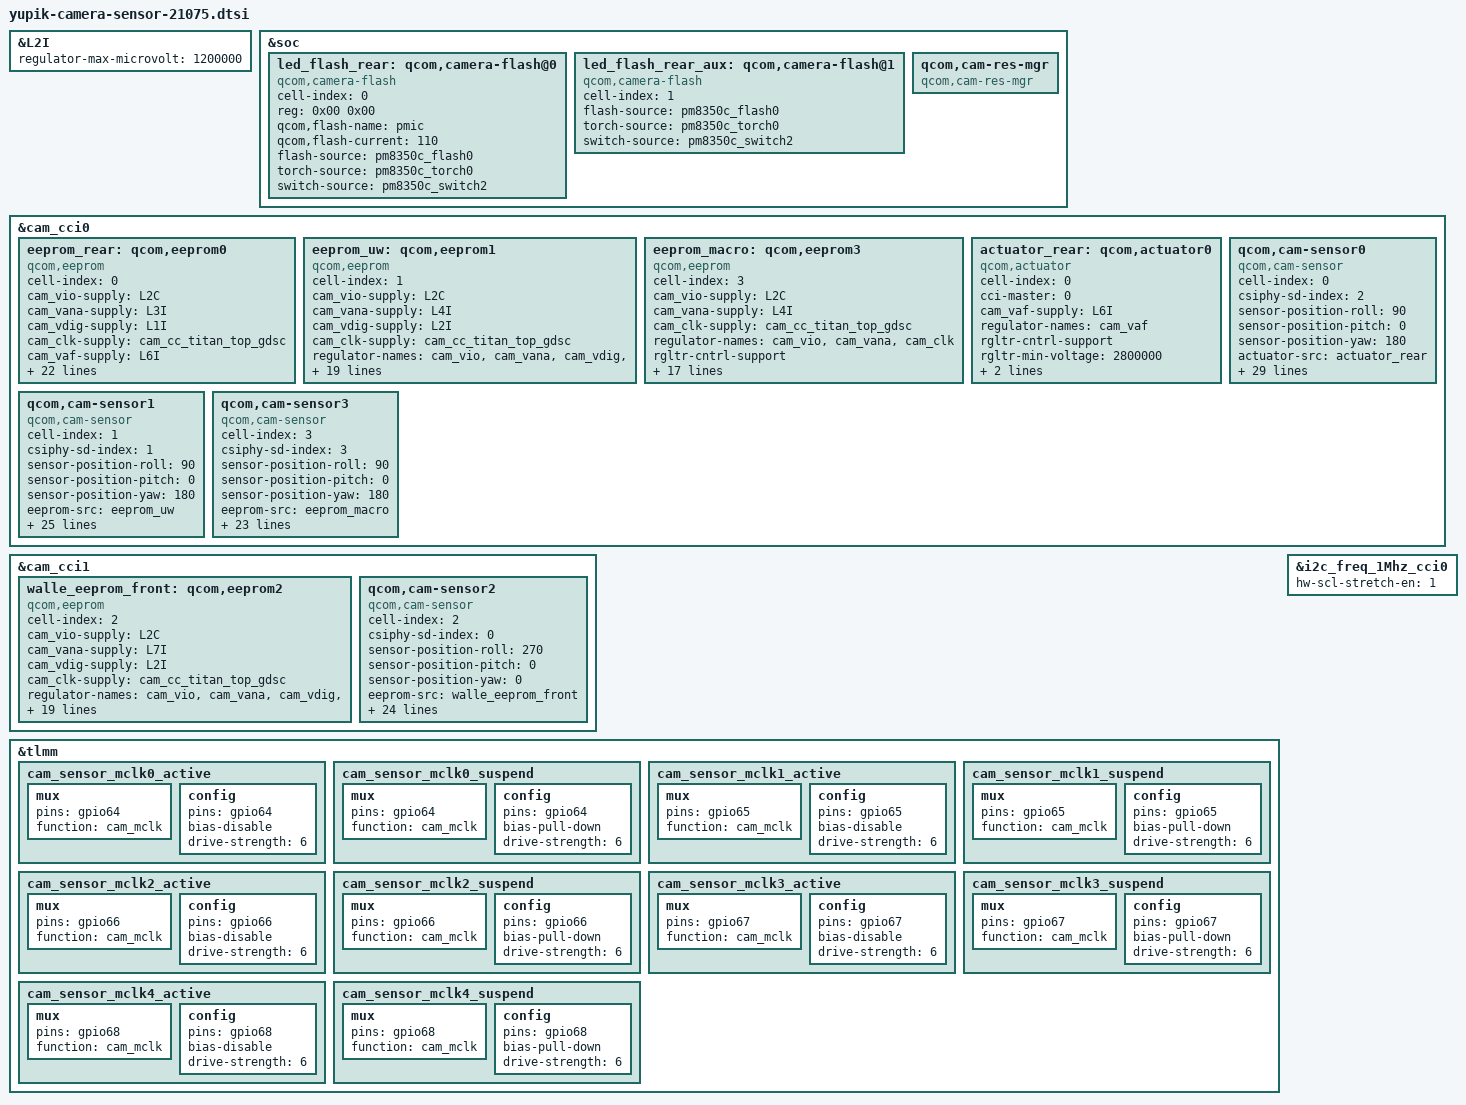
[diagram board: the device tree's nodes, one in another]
#include <dt-bindings/clock/qcom,camcc-yupik.h>

&L2I {
    regulator-max-microvolt = <1200000>;
};

&soc {
	led_flash_rear: qcom,camera-flash@0 {
		cell-index = <0>;
		reg = <0x00 0x00>;
	        compatible = "qcom,camera-flash";
		qcom,flash-name = "pmic";
		qcom,flash-current = <110>;
		flash-source = <&pm8350c_flash0>;
		torch-source = <&pm8350c_torch0>;
		switch-source = <&pm8350c_switch2>;
		status = "ok";
	};
	led_flash_rear_aux: qcom,camera-flash@1 {
		cell-index = <1>;
		compatible = "qcom,camera-flash";
		flash-source = <&pm8350c_flash0>;
		torch-source = <&pm8350c_torch0>;
		switch-source = <&pm8350c_switch2>;
		status = "ok";
	};
	qcom,cam-res-mgr {
		compatible = "qcom,cam-res-mgr";
		status = "ok";
	};
};

&cam_cci0 {
	eeprom_rear: qcom,eeprom0 {
		cell-index = <0>;
		compatible = "qcom,eeprom";
		cam_vio-supply = <&L2C>;
		cam_vana-supply = <&L3I>;
		cam_vdig-supply = <&L1I>;
		cam_clk-supply = <&cam_cc_titan_top_gdsc>;
		cam_vaf-supply = <&L6I>;
		regulator-names = "cam_vio", "cam_vana",
                           "cam_vdig","cam_clk","cam_vaf";
		rgltr-cntrl-support;
		rgltr-min-voltage = <1800000 2800000 1120000 0 2800000>;
		rgltr-max-voltage = <1800000 2800000 1120000 0 2800000>;
		rgltr-load-current = <0 60000 105000 0 103000>;
		gpio-no-mux = <0>;
		pinctrl-names = "cam_default", "cam_suspend";
		pinctrl-0 = <&cam_sensor_mclk0_active
                    &cam_sensor_active_rst0>;
		pinctrl-1 = <&cam_sensor_mclk0_suspend
                    &cam_sensor_suspend_rst0>;
		gpios = <&tlmm 64 0>,
                <&tlmm 20 0>;
		gpio-reset = <1>;
		gpio-req-tbl-num = <0 1>;
		gpio-req-tbl-flags = <1 0>;
		gpio-req-tbl-label = "CAMIF_MCLK0", "CAM_RESET0";
		cci-master = <0>;
		status = "ok";
		clocks = <&camcc CAM_CC_MCLK0_CLK>;
		clock-names = "cam_clk";
		clock-cntl-level = "nominal";
		clock-rates = <24000000>;
	};

    eeprom_uw: qcom,eeprom1 {
		cell-index = <1>;
		compatible = "qcom,eeprom";
		cam_vio-supply = <&L2C>;
		cam_vana-supply = <&L4I>;
		cam_vdig-supply = <&L2I>;
		cam_clk-supply = <&cam_cc_titan_top_gdsc>;
		regulator-names = "cam_vio", "cam_vana", "cam_vdig", "cam_clk";
		rgltr-cntrl-support;
		rgltr-min-voltage = <1800000 2800000 1200000 0>;
		rgltr-max-voltage = <1800000 2800000 1200000 0>;
		rgltr-load-current = <0 50000 250000 0>;
		gpio-no-mux = <0>;
		pinctrl-names = "cam_default", "cam_suspend";
		pinctrl-0 = <&cam_sensor_mclk1_active
                    &cam_sensor_active_rst1>;
		pinctrl-1 = <&cam_sensor_mclk1_suspend
                    &cam_sensor_suspend_rst1>;
		gpios = <&tlmm 65 0>,
                <&tlmm 21 0>;
		gpio-reset = <1>;
		gpio-req-tbl-num = <0 1>;
		gpio-req-tbl-flags = <1 0>;
		gpio-req-tbl-label = "CAMIF_MCLK1",
		                     "CAM_RESET1";
		cci-master = <1>;
		status = "ok";
		clocks = <&camcc CAM_CC_MCLK1_CLK>;
		clock-names = "cam_clk";
		clock-cntl-level = "nominal";
		clock-rates = <24000000>;
	};

    eeprom_macro: qcom,eeprom3 {
		cell-index = <3>;
		compatible = "qcom,eeprom";
		cam_vio-supply = <&L2C>;
		cam_vana-supply = <&L4I>;
		cam_clk-supply = <&cam_cc_titan_top_gdsc>;
		regulator-names = "cam_vio", "cam_vana", "cam_clk";
		rgltr-cntrl-support;
		rgltr-min-voltage = <1800000 2800000 0>;
		rgltr-max-voltage = <1800000 2800000 0>;
		rgltr-load-current = <0 80000 0>;
		gpio-no-mux = <0>;
		pinctrl-names = "cam_default", "cam_suspend";
		pinctrl-0 = <&cam_sensor_mclk3_active
				 &cam_sensor_active_rst3>;
		pinctrl-1 = <&cam_sensor_mclk3_suspend
				 &cam_sensor_suspend_rst3>;
		gpios = <&tlmm 67 0>,
		        <&tlmm 78 0>;
		gpio-reset = <1>;
		gpio-req-tbl-num = <0 1>;
		gpio-req-tbl-flags = <1 0>;
		gpio-req-tbl-label = "CAMIF_MCLK3",
		                     "CAM_RESET3";
		cci-master = <1>;
		status = "ok";
		clocks = <&camcc CAM_CC_MCLK3_CLK>;
		clock-names = "cam_clk";
		clock-cntl-level = "turbo";
		clock-rates = <24000000>;
	};

	actuator_rear: qcom,actuator0 {
		cell-index = <0>;
		compatible = "qcom,actuator";
		cci-master = <0>;
		cam_vaf-supply = <&L6I>;
		regulator-names = "cam_vaf";
		rgltr-cntrl-support;
		rgltr-min-voltage = <2800000>;
		rgltr-max-voltage = <2800000>;
		rgltr-load-current = <103000>;
	};

	/* Wide */
	qcom,cam-sensor0 {
		cell-index = <0>;
		compatible = "qcom,cam-sensor";
		csiphy-sd-index = <2>;
		sensor-position-roll = <90>;
		sensor-position-pitch = <0>;
		sensor-position-yaw = <180>;
		actuator-src = <&actuator_rear>;
		eeprom-src = <&eeprom_rear>;
		led-flash-src = <&led_flash_rear>;
		cam_vio-supply = <&L2C>;
		cam_vana-supply = <&L3I>;
		cam_vdig-supply = <&L1I>;
		cam_clk-supply = <&cam_cc_titan_top_gdsc>;
		cam_vaf-supply = <&L6I>;
		regulator-names = "cam_vio", "cam_vana",
                           "cam_vdig","cam_clk","cam_vaf";
		rgltr-cntrl-support;
		rgltr-min-voltage = <1800000 2800000 1120000 0 2800000>;
		rgltr-max-voltage = <1800000 2800000 1120000 0 2800000>;
		rgltr-load-current = <0 60000 105000 0 103000>;
		gpio-no-mux = <0>;
		pinctrl-names = "cam_default", "cam_suspend";
		pinctrl-0 = <&cam_sensor_mclk0_active
                    &cam_sensor_active_rst0>;
		pinctrl-1 = <&cam_sensor_mclk0_suspend
                    &cam_sensor_suspend_rst0>;
		gpios = <&tlmm 64 0>,
                <&tlmm 20 0>;
		gpio-reset = <1>;
		gpio-req-tbl-num = <0 1>;
		gpio-req-tbl-flags = <1 0>;
		gpio-req-tbl-label = "CAMIF_MCLK0", "CAM_RESET0";
		cci-master = <0>;
		status = "ok";
		clocks = <&camcc CAM_CC_MCLK0_CLK>;
		clock-names = "cam_clk";
		clock-cntl-level = "nominal";
		clock-rates = <24000000>;
	};

	/* UW */
	qcom,cam-sensor1 {
		cell-index = <1>;
		compatible = "qcom,cam-sensor";
		csiphy-sd-index = <1>;
		sensor-position-roll = <90>;
		sensor-position-pitch = <0>;
		sensor-position-yaw = <180>;
        eeprom-src = <&eeprom_uw>;
		led-flash-src = <&led_flash_rear_aux>;
		cam_vio-supply = <&L2C>;
		cam_vana-supply = <&L4I>;
		cam_vdig-supply = <&L2I>;
		cam_clk-supply = <&cam_cc_titan_top_gdsc>;
		regulator-names = "cam_vio", "cam_vana", "cam_vdig", "cam_clk";
		rgltr-cntrl-support;
		rgltr-min-voltage = <1800000 2800000 1200000 0>;
		rgltr-max-voltage = <1800000 2800000 1200000 0>;
		rgltr-load-current = <0 50000 250000 0>;
		gpio-no-mux = <0>;
		pinctrl-names = "cam_default", "cam_suspend";
		pinctrl-0 = <&cam_sensor_mclk1_active
                    &cam_sensor_active_rst1>;
		pinctrl-1 = <&cam_sensor_mclk1_suspend
                    &cam_sensor_suspend_rst1>;
		gpios = <&tlmm 65 0>,
                <&tlmm 21 0>;
		gpio-reset = <1>;
		gpio-req-tbl-num = <0 1>;
		gpio-req-tbl-flags = <1 0>;
		gpio-req-tbl-label = "CAMIF_MCLK1",
		                     "CAM_RESET1";
		cci-master = <1>;
		status = "ok";
		clocks = <&camcc CAM_CC_MCLK1_CLK>;
		clock-names = "cam_clk";
		clock-cntl-level = "nominal";
		clock-rates = <24000000>;
	};

	/* Macro */
	qcom,cam-sensor3 {
		cell-index = <3>;
		compatible = "qcom,cam-sensor";
		csiphy-sd-index = <3>;
		sensor-position-roll = <90>;
		sensor-position-pitch = <0>;
		sensor-position-yaw = <180>;
        eeprom-src = <&eeprom_macro>;
		led-flash-src = <&led_flash_rear>;
		cam_vio-supply = <&L2C>;
		cam_vana-supply = <&L4I>;
		cam_clk-supply = <&cam_cc_titan_top_gdsc>;
		regulator-names = "cam_vio", "cam_vana", "cam_clk";
		rgltr-cntrl-support;
		rgltr-min-voltage = <1800000 2800000 0>;
		rgltr-max-voltage = <1800000 2800000 0>;
		rgltr-load-current = <0 80000 0>;
		gpio-no-mux = <0>;
		pinctrl-names = "cam_default", "cam_suspend";
		pinctrl-0 = <&cam_sensor_mclk3_active
				 &cam_sensor_active_rst3>;
		pinctrl-1 = <&cam_sensor_mclk3_suspend
				 &cam_sensor_suspend_rst3>;
		gpios = <&tlmm 67 0>,
		        <&tlmm 78 0>;
		gpio-reset = <1>;
		gpio-req-tbl-num = <0 1>;
		gpio-req-tbl-flags = <1 0>;
		gpio-req-tbl-label = "CAMIF_MCLK3",
		                     "CAM_RESET3";
		cci-master = <1>;
		status = "ok";
		clocks = <&camcc CAM_CC_MCLK3_CLK>;
		clock-names = "cam_clk";
		clock-cntl-level = "turbo";
		clock-rates = <24000000>;
	};
};

&cam_cci1 {
	walle_eeprom_front: qcom,eeprom2 {
		cell-index = <2>;
		compatible = "qcom,eeprom";
        cam_vio-supply = <&L2C>;
        cam_vana-supply = <&L7I>;
        cam_vdig-supply = <&L2I>;
        cam_clk-supply = <&cam_cc_titan_top_gdsc>;
        regulator-names = "cam_vio", "cam_vana", "cam_vdig", "cam_clk";
        rgltr-cntrl-support;
        rgltr-min-voltage = <1800000 2800000 1056000 0>;
        rgltr-max-voltage = <1800000 2800000 1200000 0>;
        rgltr-load-current = <0 80000 105000 0>;
        gpio-no-mux = <0>;
        pinctrl-names = "cam_default", "cam_suspend";
        pinctrl-0 = <&cam_sensor_mclk2_active
                    &cam_sensor_active_rst2>;
        pinctrl-1 = <&cam_sensor_mclk2_suspend
                    &cam_sensor_suspend_rst2>;
        gpios = <&tlmm 66 0>,
                <&tlmm 77 0>;
        gpio-reset = <1>;
        gpio-req-tbl-num = <0 1>;
        gpio-req-tbl-flags = <1 0>;
        gpio-req-tbl-label = "CAMIF_MCLK2","CAM_RESET2";
        cci-master = <1>;
        status = "ok";
        clocks = <&camcc CAM_CC_MCLK2_CLK>;
        clock-names = "cam_clk";
        clock-cntl-level = "turbo";
        clock-rates = <24000000>;
	};

	/* Front */
	qcom,cam-sensor2 {
        cell-index = <2>;
        compatible = "qcom,cam-sensor";
        csiphy-sd-index = <0>;
        sensor-position-roll = <270>;
        sensor-position-pitch = <0>;
        sensor-position-yaw = <0>;
        eeprom-src = <&walle_eeprom_front>;
        cam_vio-supply = <&L2C>;
        cam_vana-supply = <&L7I>;
        cam_vdig-supply = <&L2I>;
        cam_clk-supply = <&cam_cc_titan_top_gdsc>;
        regulator-names = "cam_vio", "cam_vana", "cam_vdig", "cam_clk";
        rgltr-cntrl-support;
        rgltr-min-voltage = <1800000 2800000 1056000 0>;
        rgltr-max-voltage = <1800000 2800000 1200000 0>;
        rgltr-load-current = <0 80000 105000 0>;
        gpio-no-mux = <0>;
        pinctrl-names = "cam_default", "cam_suspend";
        pinctrl-0 = <&cam_sensor_mclk2_active
                    &cam_sensor_active_rst2>;
        pinctrl-1 = <&cam_sensor_mclk2_suspend
                    &cam_sensor_suspend_rst2>;
        gpios = <&tlmm 66 0>,
                <&tlmm 77 0>;
        gpio-reset = <1>;
        gpio-req-tbl-num = <0 1>;
        gpio-req-tbl-flags = <1 0>;
        gpio-req-tbl-label = "CAMIF_MCLK2","CAM_RESET2";
        cci-master = <1>;
        status = "ok";
        clocks = <&camcc CAM_CC_MCLK2_CLK>;
        clock-names = "cam_clk";
        clock-cntl-level = "turbo";
        clock-rates = <24000000>;
	};
};

&tlmm {

    cam_sensor_mclk0_active: cam_sensor_mclk0_active {
        /* MCLK0 */
        mux {
            pins = "gpio64";
            function = "cam_mclk";
        };

        config {
            pins = "gpio64";
            bias-disable; /* No PULL */
            drive-strength = <6>; /* 2 MA */
        };
    };

    cam_sensor_mclk0_suspend: cam_sensor_mclk0_suspend {
        /* MCLK0 */
        mux {
            pins = "gpio64";
            function = "cam_mclk";
        };

        config {
            pins = "gpio64";
            bias-pull-down; /* PULL DOWN */
            drive-strength = <6>; /* 2 MA */
        };
    };

    cam_sensor_mclk1_active: cam_sensor_mclk1_active {
        /* MCLK1 */
        mux {
            pins = "gpio65";
            function = "cam_mclk";
        };

        config {
            pins = "gpio65";
            bias-disable; /* No PULL */
            drive-strength = <6>; /* 2 MA */
        };
    };

    cam_sensor_mclk1_suspend: cam_sensor_mclk1_suspend {
        /* MCLK1 */
        mux {
            pins = "gpio65";
            function = "cam_mclk";
        };

        config {
            pins = "gpio65";
            bias-pull-down; /* PULL DOWN */
            drive-strength = <6>; /* 2 MA */
        };
    };

    cam_sensor_mclk2_active: cam_sensor_mclk2_active {
        /* MCLK2 */
        mux {
            pins = "gpio66";
            function = "cam_mclk";
        };

        config {
            pins = "gpio66";
            bias-disable; /* No PULL */
            drive-strength = <6>; /* 2 MA */
        };
    };

    cam_sensor_mclk2_suspend: cam_sensor_mclk2_suspend {
        /* MCLK2 */
        mux {
            pins = "gpio66";
            function = "cam_mclk";
        };

        config {
            pins = "gpio66";
            bias-pull-down; /* PULL DOWN */
            drive-strength = <6>; /* 2 MA */
        };
    };

    cam_sensor_mclk3_active: cam_sensor_mclk3_active {
        /* MCLK3 */
        mux {
            pins = "gpio67";
            function = "cam_mclk";
        };

        config {
            pins = "gpio67";
            bias-disable; /* No PULL */
            drive-strength = <6>; /* 2 MA */
        };
    };

    cam_sensor_mclk3_suspend: cam_sensor_mclk3_suspend {
        /* MCLK3 */
        mux {
            pins = "gpio67";
            function = "cam_mclk";
        };

        config {
            pins = "gpio67";
            bias-pull-down; /* PULL DOWN */
            drive-strength = <6>; /* 2 MA */
        };
    };

    cam_sensor_mclk4_active: cam_sensor_mclk4_active {
        /* MCLK4 */
        mux {
            pins = "gpio68";
            function = "cam_mclk";
        };

        config {
            pins = "gpio68";
            bias-disable; /* No PULL */
            drive-strength = <6>; /* 2 MA */
        };
    };

    cam_sensor_mclk4_suspend: cam_sensor_mclk4_suspend {
        /* MCLK4 */
        mux {
            pins = "gpio68";
            function = "cam_mclk";
        };

        config {
            pins = "gpio68";
            bias-pull-down; /* PULL DOWN */
            drive-strength = <6>; /* 2 MA */
        };
    };
};

&i2c_freq_1Mhz_cci0 {
    hw-scl-stretch-en = <1>;
};
